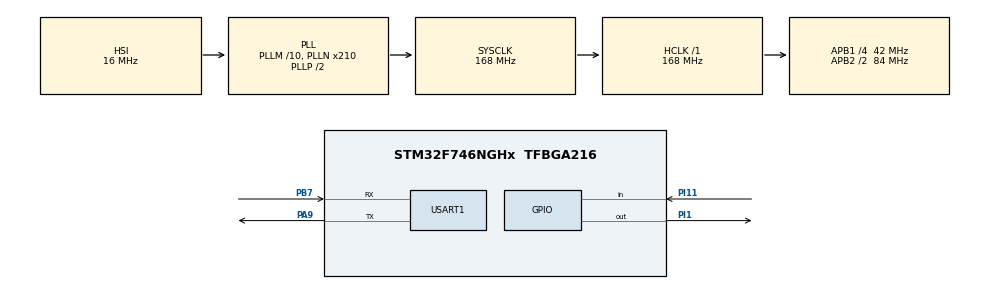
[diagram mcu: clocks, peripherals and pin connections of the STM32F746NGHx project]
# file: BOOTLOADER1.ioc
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CORTEX_M7.AccessPermission_S-Cortex_Memory_Protection_Unit_Region1_Settings_S=MPU_REGION_FULL_ACCESS
CORTEX_M7.AccessPermission_Spec=MPU_REGION_PRIV_RO_URO
CORTEX_M7.BaseAddress_S-Cortex_Memory_Protection_Unit_Region1_Settings_S=0x08010000
CORTEX_M7.BaseAddress_Spec=0x08000000
CORTEX_M7.DisableExec_S-Cortex_Memory_Protection_Unit_Region1_Settings_S=MPU_INSTRUCTION_ACCESS_DISABLE
CORTEX_M7.DisableExec_Spec=MPU_INSTRUCTION_ACCESS_ENABLE
CORTEX_M7.Enable_S-Cortex_Memory_Protection_Unit_Region1_Settings_S=MPU_REGION_ENABLE
CORTEX_M7.IsCacheable_S-Cortex_Memory_Protection_Unit_Region1_Settings_S=MPU_ACCESS_NOT_CACHEABLE
CORTEX_M7.IsCacheable_Spec=MPU_ACCESS_CACHEABLE
CORTEX_M7.IsShareable_Spec=MPU_ACCESS_NOT_SHAREABLE
CORTEX_M7.Size_S-Cortex_Memory_Protection_Unit_Region1_Settings_S=MPU_REGION_SIZE_32KB
CORTEX_M7.Size_Spec=MPU_REGION_SIZE_64KB
CORTEX_M7.SubRegionDisable_Spec=0x0
CORTEX_M7.default_mode_Activation=1
Mcu.Family=STM32F7
Mcu.Name=STM32F746NGHx
Mcu.Package=TFBGA216
NVIC.PriorityGroup=NVIC_PRIORITYGROUP_4
PA13.Mode=Serial_Wire
PA13.Signal=SYS_JTMS-SWDIO
PA14.Mode=Serial_Wire
PA14.Signal=SYS_JTCK-SWCLK
PA9.Mode=Asynchronous
PA9.Signal=USART1_TX
PB7.Mode=Asynchronous
PB7.Signal=USART1_RX
PI1.Signal=GPIO_Output
PI11.Signal=GPIO_Input
ProjectManager.HeapSize=0x200
ProjectManager.StackSize=0x400
ProjectManager.TargetToolchain=CMake
RCC.AHBFreq_Value=168000000
RCC.APB1CLKDivider=RCC_HCLK_DIV4
RCC.APB1Freq_Value=42000000
RCC.APB1TimFreq_Value=84000000
RCC.APB2CLKDivider=RCC_HCLK_DIV2
RCC.APB2Freq_Value=84000000
RCC.APB2TimFreq_Value=168000000
RCC.CortexFreq_Value=168000000
RCC.HCLKFreq_Value=168000000
RCC.HSE_VALUE=25000000
RCC.HSI_VALUE=16000000
RCC.LSE_VALUE=32768
RCC.PLLM=10
RCC.PLLN=210
RCC.PLLSourceVirtual=RCC_PLLSOURCE_HSI
RCC.SYSCLKFreq_VALUE=168000000
RCC.SYSCLKSource=RCC_SYSCLKSOURCE_PLLCLK
RCC.USBFreq_Value=168000000
RCC.VCOOutputFreq_Value=336000000
USART1.VirtualMode-Asynchronous=VM_ASYNC
board=STM32F746G-DISCO

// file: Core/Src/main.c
/* USER CODE BEGIN Header */
/**
  ******************************************************************************
  * @file           : main.c
  * @brief          : Main program body
  ******************************************************************************
  * @attention
  *
  * Copyright (c) 2025 STMicroelectronics.
  * All rights reserved.
  *
  * This software is licensed under terms that can be found in the LICENSE file
  * in the root directory of this software component.
  * If no LICENSE file comes with this software, it is provided AS-IS.
  *
  ******************************************************************************
  */
/* USER CODE END Header */
#include "main.h"

/* USER CODE BEGIN Includes */
#include "bootloader_core.h"
#include "system_interface.h"
/* USER CODE END Includes */

UART_HandleTypeDef huart1;

void SystemClock_Config(void);
static void MPU_Config(void);
static void MX_GPIO_Init(void);
static void MX_USART1_UART_Init(void);

int main(void)
{

  /* MPU Configuration--------------------------------------------------------*/
  MPU_Config();

  /* MCU Configuration--------------------------------------------------------*/

  /* Reset of all peripherals, Initializes the Flash interface and the Systick. */
  HAL_Init();

  /* Configure the system clock */
  SystemClock_Config();

  /* Initialize all configured peripherals */
  MX_GPIO_Init();
  MX_USART1_UART_Init();
  /* USER CODE BEGIN 2 */
  Bootloader_Run(Sys_GetInterface());
  /* USER CODE END 2 */

  /* Infinite loop */
  while (1)
  {

  }
}

void SystemClock_Config(void)
{
  RCC_OscInitTypeDef RCC_OscInitStruct = {0};
  RCC_ClkInitTypeDef RCC_ClkInitStruct = {0};

  /** Configure the main internal regulator output voltage
  */
  __HAL_RCC_PWR_CLK_ENABLE();
  __HAL_PWR_VOLTAGESCALING_CONFIG(PWR_REGULATOR_VOLTAGE_SCALE2);

  /** Initializes the RCC Oscillators according to the specified parameters
  * in the RCC_OscInitTypeDef structure.
  */
  RCC_OscInitStruct.OscillatorType = RCC_OSCILLATORTYPE_HSI;
  RCC_OscInitStruct.HSIState = RCC_HSI_ON;
  RCC_OscInitStruct.HSICalibrationValue = RCC_HSICALIBRATION_DEFAULT;
  RCC_OscInitStruct.PLL.PLLState = RCC_PLL_ON;
  RCC_OscInitStruct.PLL.PLLSource = RCC_PLLSOURCE_HSI;
  RCC_OscInitStruct.PLL.PLLM = 10;
  RCC_OscInitStruct.PLL.PLLN = 210;
  RCC_OscInitStruct.PLL.PLLP = RCC_PLLP_DIV2;
  RCC_OscInitStruct.PLL.PLLQ = 2;
  if (HAL_RCC_OscConfig(&RCC_OscInitStruct) != HAL_OK)
  {
    Error_Handler();
  }

  /** Initializes the CPU, AHB and APB buses clocks
  */
  RCC_ClkInitStruct.ClockType = RCC_CLOCKTYPE_HCLK|RCC_CLOCKTYPE_SYSCLK
                              |RCC_CLOCKTYPE_PCLK1|RCC_CLOCKTYPE_PCLK2;
  RCC_ClkInitStruct.SYSCLKSource = RCC_SYSCLKSOURCE_PLLCLK;
  RCC_ClkInitStruct.AHBCLKDivider = RCC_SYSCLK_DIV1;
  RCC_ClkInitStruct.APB1CLKDivider = RCC_HCLK_DIV4;
  RCC_ClkInitStruct.APB2CLKDivider = RCC_HCLK_DIV2;

  if (HAL_RCC_ClockConfig(&RCC_ClkInitStruct, FLASH_LATENCY_5) != HAL_OK)
  {
    Error_Handler();
  }
}

static void MX_USART1_UART_Init(void)
{

  huart1.Instance = USART1;
  huart1.Init.BaudRate = 115200;
  huart1.Init.WordLength = UART_WORDLENGTH_8B;
  huart1.Init.StopBits = UART_STOPBITS_1;
  huart1.Init.Parity = UART_PARITY_NONE;
  huart1.Init.Mode = UART_MODE_TX_RX;
  huart1.Init.HwFlowCtl = UART_HWCONTROL_NONE;
  huart1.Init.OverSampling = UART_OVERSAMPLING_16;
  huart1.Init.OneBitSampling = UART_ONE_BIT_SAMPLE_DISABLE;
  huart1.AdvancedInit.AdvFeatureInit = UART_ADVFEATURE_NO_INIT;
  if (HAL_UART_Init(&huart1) != HAL_OK)
  {
    Error_Handler();
  }

}

static void MX_GPIO_Init(void)
{
  GPIO_InitTypeDef GPIO_InitStruct = {0};

  /* GPIO Ports Clock Enable */
  __HAL_RCC_GPIOA_CLK_ENABLE();
  __HAL_RCC_GPIOB_CLK_ENABLE();
  __HAL_RCC_GPIOI_CLK_ENABLE();

  /*Configure GPIO pin Output Level */
  HAL_GPIO_WritePin(GPIOI, GPIO_PIN_1, GPIO_PIN_RESET);

  /*Configure GPIO pin : PI1 */
  GPIO_InitStruct.Pin = GPIO_PIN_1;
  GPIO_InitStruct.Mode = GPIO_MODE_OUTPUT_PP;
  GPIO_InitStruct.Pull = GPIO_NOPULL;
  GPIO_InitStruct.Speed = GPIO_SPEED_FREQ_LOW;
  HAL_GPIO_Init(GPIOI, &GPIO_InitStruct);

  /*Configure GPIO pin : PI11 */
  GPIO_InitStruct.Pin = GPIO_PIN_11;
  GPIO_InitStruct.Mode = GPIO_MODE_INPUT;
  GPIO_InitStruct.Pull = GPIO_NOPULL;
  HAL_GPIO_Init(GPIOI, &GPIO_InitStruct);

}

 /* MPU Configuration */

void MPU_Config(void)
{
  MPU_Region_InitTypeDef MPU_InitStruct = {0};

  /* Disables the MPU */
  HAL_MPU_Disable();

  /** Initializes and configures the Region and the memory to be protected
  */
  MPU_InitStruct.Enable = MPU_REGION_ENABLE;
  MPU_InitStruct.Number = MPU_REGION_NUMBER0;
  MPU_InitStruct.BaseAddress = 0x08000000;
  MPU_InitStruct.Size = MPU_REGION_SIZE_64KB;
  MPU_InitStruct.SubRegionDisable = 0x0;
  MPU_InitStruct.TypeExtField = MPU_TEX_LEVEL0;
  MPU_InitStruct.AccessPermission = MPU_REGION_PRIV_RO_URO;
  MPU_InitStruct.DisableExec = MPU_INSTRUCTION_ACCESS_ENABLE;
  MPU_InitStruct.IsShareable = MPU_ACCESS_NOT_SHAREABLE;
  MPU_InitStruct.IsCacheable = MPU_ACCESS_CACHEABLE;
  MPU_InitStruct.IsBufferable = MPU_ACCESS_NOT_BUFFERABLE;

  HAL_MPU_ConfigRegion(&MPU_InitStruct);

  /** Initializes and configures the Region and the memory to be protected
  */
  MPU_InitStruct.Number = MPU_REGION_NUMBER1;
  MPU_InitStruct.BaseAddress = 0x08010000;
  MPU_InitStruct.Size = MPU_REGION_SIZE_32KB;
  MPU_InitStruct.AccessPermission = MPU_REGION_FULL_ACCESS;
  MPU_InitStruct.DisableExec = MPU_INSTRUCTION_ACCESS_DISABLE;
  MPU_InitStruct.IsCacheable = MPU_ACCESS_NOT_CACHEABLE;

  HAL_MPU_ConfigRegion(&MPU_InitStruct);
  /* Enables the MPU */
  HAL_MPU_Enable(MPU_PRIVILEGED_DEFAULT);

}

void Error_Handler(void)
{
  __disable_irq();
  while (1)
  {
  }
}
